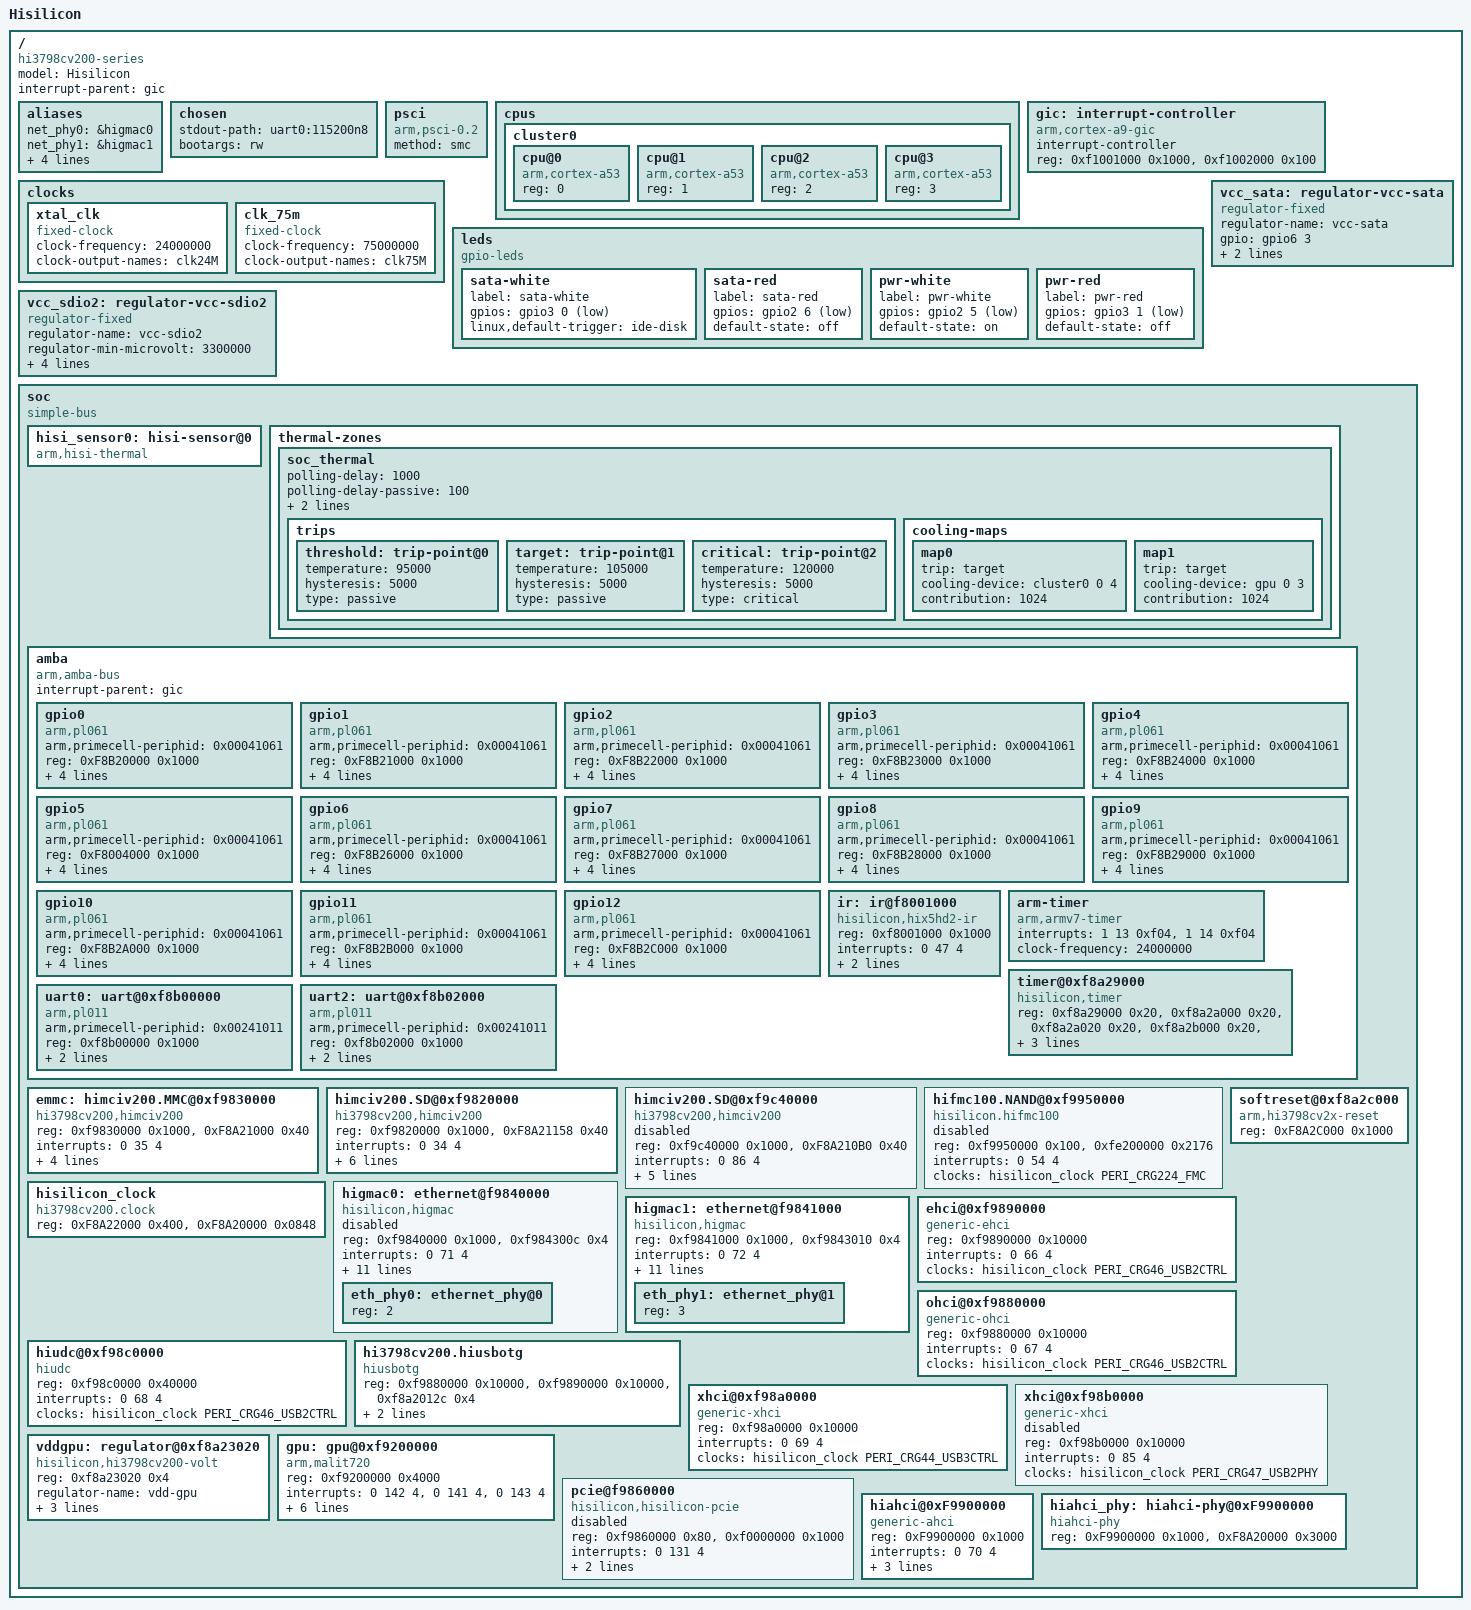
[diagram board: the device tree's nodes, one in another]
/dts-v1/;

#include <dt-bindings/clock/hi3798cv200-clock.h>
#include <dt-bindings/gpio/gpio.h>

/ {
	model = "Hisilicon";
	compatible = "hi3798cv200-series";
	#address-cells = <1>;
	#size-cells = <1>;
	interrupt-parent = <&gic>;

	aliases {
		net_phy0 = &higmac0;
		net_phy1 = &higmac1;
		net_phy_addr0 = &eth_phy0;
		net_phy_addr1 = &eth_phy1;
		emmc = &emmc;
		uart0 = &uart0;
	};

	chosen {
		stdout-path = "uart0:115200n8";
		bootargs = "rw";
	};

	psci {
		compatible = "arm,psci-0.2";
		method = "smc";
	};

	cpus {
		cluster0: cluster0 {
			#address-cells = <1>;
			#size-cells = <0>;

			/* cooling options */
			#cooling-cells = <2>; /* min followed by max */
			
			cpu@0 {
				compatible = "arm,cortex-a53";
				device_type = "cpu";
				reg = <0>;
			};
			cpu@1 {
				compatible = "arm,cortex-a53";
				device_type = "cpu";
				reg = <1>;
			};
			cpu@2 {
				compatible = "arm,cortex-a53";
				device_type = "cpu";
				reg = <2>;
			};
			cpu@3 {
				compatible = "arm,cortex-a53";
				device_type = "cpu";
				reg = <3>;
			};

		}; /* cluster0 */
	}; /* cpus */

	gic: interrupt-controller {
		compatible = "arm,cortex-a9-gic";
		#interrupt-cells = <3>;
		#address-cells = <0>;
		interrupt-controller;
		reg = <0xf1001000 0x1000>,
		      <0xf1002000 0x100>;
	};

	clocks {
		xtal_clk: xtal_clk {
			compatible = "fixed-clock";
			#clock-cells = <0>;
			clock-frequency = <24000000>;
			clock-output-names = "clk24M";
		};

		clk_75m: clk_75m{
			compatible = "fixed-clock";
			#clock-cells = <0>;
			clock-frequency = <75000000>;
			clock-output-names = "clk75M";
		};
	};

	leds {
		compatible = "gpio-leds";

		sata-white {
			label = "sata-white";
			gpios = <&gpio3 0 GPIO_ACTIVE_LOW>;
			linux,default-trigger = "ide-disk";
		};

		sata-red {
			label = "sata-red";
			gpios = <&gpio2 6 GPIO_ACTIVE_LOW>;
			default-state = "off";
		};

		pwr-white {
			label = "pwr-white";
			gpios = <&gpio2 5 GPIO_ACTIVE_LOW>;
			default-state = "on";
		};

		pwr-red {
			label = "pwr-red";
			gpios = <&gpio3 1 GPIO_ACTIVE_LOW>;
			default-state = "off";
		};
	};

	vcc_sata: regulator-vcc-sata {
		compatible = "regulator-fixed";
		regulator-name = "vcc-sata";
		gpio = <&gpio6 3 GPIO_ACTIVE_HIGH>;
		regulator-boot-on;
		enable-active-high;
	};

	vcc_sdio2: regulator-vcc-sdio2 {
		compatible = "regulator-fixed";
		regulator-name = "vcc-sdio2";
		regulator-min-microvolt = <3300000>;
		regulator-max-microvolt = <3300000>;
		gpio = <&gpio8 1 GPIO_ACTIVE_HIGH>;
		enable-active-high;
		startup-delay-us = <100000>;
	};

	soc {
		#address-cells = <1>;
		#size-cells = <1>;
		compatible = "simple-bus";
		device_type = "soc";
		ranges = <0x0 0x0 0xffffffff>;

		hisi_sensor0: hisi-sensor@0 {
			compatible = "arm,hisi-thermal";
			#thermal-sensor-cells = <1>;
		};

		thermal-zones {
			soc_thermal {
				polling-delay = <1000>;
				polling-delay-passive = <100>;
				sustainable-power = <2500>;

				thermal-sensors = <&hisi_sensor0 0>;

				trips {
					threshold: trip-point@0 {
						temperature = <95000>;
						hysteresis = <5000>;
						type = "passive";
					};
					target: trip-point@1 {
						temperature = <105000>;
						hysteresis = <5000>;
						type = "passive";
					};
					critical: trip-point@2 {
						temperature = <120000>;
						hysteresis = <5000>;
						type = "critical";
					};
				};

				cooling-maps {
					map0 {
					     trip = <&target>;
					     cooling-device = <&cluster0 0 4>;
					     contribution = <1024>;
					};
					map1 {
					    trip = <&target>;
					    cooling-device = <&gpu 0 3>;
					    contribution = <1024>;
					};
				};
			};
		};

		amba {
			compatible = "arm,amba-bus";
			#address-cells = <1>;
			#size-cells = <1>;
			interrupt-parent = <&gic>;
			ranges;

			gpio0: gpio0 {
				compatible = "arm,pl061", "arm,primecell";
				arm,primecell-periphid = <0x00041061>;
				reg = <0xF8B20000 0x1000>;
				interrupts = <0 108 0x4>;
				gpio-controller;
				#gpio-cells = <2>;
				interrupt-controller;
				#interrupt-cells = <2>;
				clocks = <&xtal_clk>;
				clock-names = "apb_pclk";
			};

			gpio1: gpio1 {
				compatible = "arm,pl061", "arm,primecell";
				arm,primecell-periphid = <0x00041061>;
				reg = <0xF8B21000 0x1000>;
				interrupts = <0 109 4>;
				gpio-controller;
				#gpio-cells = <2>;
				interrupt-controller;
				#interrupt-cells = <2>;
				clocks = <&xtal_clk>;
				clock-names = "apb_pclk";
			};

			gpio2: gpio2 {
				compatible = "arm,pl061", "arm,primecell";
				arm,primecell-periphid = <0x00041061>;
				reg = <0xF8B22000 0x1000>;
				interrupts = <0 110 4>;
				gpio-controller;
				#gpio-cells = <2>;
				interrupt-controller;
				#interrupt-cells = <2>;
				clocks = <&xtal_clk>;
				clock-names = "apb_pclk";
			};

			gpio3: gpio3 {
				compatible = "arm,pl061", "arm,primecell";
				arm,primecell-periphid = <0x00041061>;
				reg = <0xF8B23000 0x1000>;
				interrupts = <0 111 4>;
				gpio-controller;
				#gpio-cells = <2>;
				interrupt-controller;
				#interrupt-cells = <2>;
				clocks = <&xtal_clk>;
				clock-names = "apb_pclk";
			};

			gpio4: gpio4 {
				compatible = "arm,pl061", "arm,primecell";
				arm,primecell-periphid = <0x00041061>;
				reg = <0xF8B24000 0x1000>;
				interrupts = <0 112 4>;
				gpio-controller;
				#gpio-cells = <2>;
				interrupt-controller;
				#interrupt-cells = <2>;
				clocks = <&xtal_clk>;
				clock-names = "apb_pclk";
			};

			gpio5: gpio5 {
				compatible = "arm,pl061", "arm,primecell";
				arm,primecell-periphid = <0x00041061>;
				reg = <0xF8004000 0x1000>;
				interrupts = <0 113 0>;
				gpio-controller;
				#gpio-cells = <2>;
				interrupt-controller;
				#interrupt-cells = <2>;
				clocks = <&xtal_clk>;
				clock-names = "apb_pclk";
			};

			gpio6: gpio6 {
				compatible = "arm,pl061", "arm,primecell";
				arm,primecell-periphid = <0x00041061>;
				reg = <0xF8B26000 0x1000>;
				interrupts = <0 114 4>;
				gpio-controller;
				#gpio-cells = <2>;
				interrupt-controller;
				#interrupt-cells = <2>;
				clocks = <&xtal_clk>;
				clock-names = "apb_pclk";
			};

			gpio7: gpio7 {
				compatible = "arm,pl061", "arm,primecell";
				arm,primecell-periphid = <0x00041061>;
				reg = <0xF8B27000 0x1000>;
				interrupts = <0 115 4>;
				gpio-controller;
				#gpio-cells = <2>;
				interrupt-controller;
				#interrupt-cells = <2>;
				clocks = <&xtal_clk>;
				clock-names = "apb_pclk";
			};

			gpio8: gpio8 {
				compatible = "arm,pl061", "arm,primecell";
				arm,primecell-periphid = <0x00041061>;
				reg = <0xF8B28000 0x1000>;
				interrupts = <0 116 4>;
				gpio-controller;
				#gpio-cells = <2>;
				interrupt-controller;
				#interrupt-cells = <2>;
				clocks = <&xtal_clk>;
				clock-names = "apb_pclk";
			};

			gpio9: gpio9 {
				compatible = "arm,pl061", "arm,primecell";
				arm,primecell-periphid = <0x00041061>;
				reg = <0xF8B29000 0x1000>;
				interrupts = <0 117 4>;
				gpio-controller;
				#gpio-cells = <2>;
				interrupt-controller;
				#interrupt-cells = <2>;
				clocks = <&xtal_clk>;
				clock-names = "apb_pclk";
			};

			gpio10: gpio10 {
				compatible = "arm,pl061", "arm,primecell";
				arm,primecell-periphid = <0x00041061>;
				reg = <0xF8B2A000 0x1000>;
				interrupts = <0 118 4>;
				gpio-controller;
				#gpio-cells = <2>;
				interrupt-controller;
				#interrupt-cells = <2>;
				clocks = <&xtal_clk>;
				clock-names = "apb_pclk";
			};

			gpio11: gpio11 {
				compatible = "arm,pl061", "arm,primecell";
				arm,primecell-periphid = <0x00041061>;
				reg = <0xF8B2B000 0x1000>;
				interrupts = <0 119 4>;
				gpio-controller;
				#gpio-cells = <2>;
				interrupt-controller;
				#interrupt-cells = <2>;
				clocks = <&xtal_clk>;
				clock-names = "apb_pclk";
			};

			gpio12: gpio12 {
				compatible = "arm,pl061", "arm,primecell";
				arm,primecell-periphid = <0x00041061>;
				reg = <0xF8B2C000 0x1000>;
				interrupts = <0 120 4>;
				gpio-controller;
				#gpio-cells = <2>;
				interrupt-controller;
				#interrupt-cells = <2>;
				clocks = <&xtal_clk>;
				clock-names = "apb_pclk";
			};

			ir: ir@f8001000 {
				compatible = "hisilicon,hix5hd2-ir";
				reg = <0xf8001000 0x1000>;
				interrupts = <0 47 4>;
				clocks = <&hisilicon_clock HIIR_CLK>;
				linux,rc-map-name = "rc-atto";
			};

			arm-timer {
				compatible = "arm,armv7-timer";
				interrupts = <1 13 0xf04>,
				             <1 14 0xf04>;
				clock-frequency = <24000000>;
			};

			timer@0xf8a29000 {
				compatible = "hisilicon,timer";
				reg = <0xf8a29000 0x20>, /* clocksource */
				      <0xf8a2a000 0x20>, /* local timer for each cpu */
				      <0xf8a2a020 0x20>,
				      <0xf8a2b000 0x20>,
				      <0xf8a2b020 0x20>;
				interrupts = <0 26 4>, /* irq of local timer */
					     <0 59 4>,
					     <0 27 4>,
					     <0 60 4>;
				clocks = <&xtal_clk>;
				clock-names = "apb_pclk";
			};

			uart0: uart@0xf8b00000 {
				compatible = "arm,pl011", "arm,primecell";
				arm,primecell-periphid = <0x00241011>;
				reg = <0xf8b00000 0x1000>;
				interrupts = <0 49 4>;
				clocks = <&clk_75m>;
				clock-names = "apb_pclk";
			};

			uart2: uart@0xf8b02000 {
				compatible = "arm,pl011", "arm,primecell";
				arm,primecell-periphid = <0x00241011>;
				reg = <0xf8b02000 0x1000>;
				interrupts = <0 51 4>;
				clocks = <&clk_75m>;
				clock-names = "apb_pclk";
			};

		};

		emmc: himciv200.MMC@0xf9830000 {
			compatible = "hi3798cv200,himciv200";
			reg = <0xf9830000 0x1000>,<0xF8A21000 0x40>;
			interrupts = <0 35 4>;

			clocks = <&hisilicon_clock PERI_CRG40_SDIO1>;
			clock-names = "clk";

			caps = <0x80000847>;
			caps2 = <0x0>;
			max-frequency = <100000000>;
			status = "okay";
		};

		himciv200.SD@0xf9820000 {
			compatible = "hi3798cv200,himciv200";
			reg = <0xf9820000 0x1000>,<0xF8A21158 0x40>;
			interrupts = <0 34 4>;

			clocks = <&hisilicon_clock PERI_CRG39_SDIO0>;
			clock-names = "clk";

			ldo-addr  = <0xf8a2011c>;
			ldo-shift = <0>;

			caps = <0x8000000f>;
			caps2 = <0x4000>;
			max-frequency = <50000000>;
			status = "okay";
		};

		himciv200.SD@0xf9c40000 {
			compatible = "hi3798cv200,himciv200";
			reg = <0xf9c40000 0x1000>,<0xF8A210B0 0x40>;
			interrupts = <0 86 4>;

			clocks = <&hisilicon_clock PERI_CRG163_SDIO2>;
			clock-names = "clk";

			caps = <0x8000000f>;
			caps2 = <0x4000>;
			max-frequency = <50000000>;
			vmmc-supply = <&vcc_sdio2>;
			status = "disabled";
		};

		hifmc100.NAND@0xf9950000 {
			compatible = "hisilicon.hifmc100";
			reg = <0xf9950000 0x100>, <0xfe200000 0x2176>;
			interrupts = <0 54 4>;

			clocks = <&hisilicon_clock PERI_CRG224_FMC>;
			clock-names = "clk";
			status = "disabled";
		};

		hisilicon_clock: hisilicon_clock {
			compatible = "hi3798cv200.clock","hisilicon,clock-reset";
			reg = <0xF8A22000 0x400>, <0xF8A20000 0x0848>;
			#clock-cells = <1>;
			#reset-cells = <2>;
		};

		higmac0: ethernet@f9840000 {
			compatible = "hisilicon,higmac";
			reg = <0xf9840000 0x1000>,<0xf984300c 0x4>;
			interrupts = <0 71 4>;

			clocks = <&hisilicon_clock HIGMAC_MAC0_CLK>,
					<&hisilicon_clock HIGMAC_MAC_IF0_CLK>;
			clock-names = "higmac_clk",
					"macif_clk";

			resets = <&hisilicon_clock PERI_CRG51_GSF HIGMAC_PORT0_RST_BIT>,
					<&hisilicon_clock PERI_CRG51_GSF HIGMAC_MACIF0_RST_BIT>,
					<&hisilicon_clock PERI_CRG51_GSF HIGMAC_PHY0_RST_BIT>;
			reset-names = "port_reset",
					"macif_reset",
					"phy_reset";

			#address-cells = <1>;
			#size-cells = <0>;

			mac-address = [00 00 00 00 00 00];

			phy-handle = <&eth_phy0>;
			phy-mode = "mii";
			phy-gpio-base = <0>;
			phy-gpio-bit = <0>;

			status = "disabled";

			eth_phy0: ethernet_phy@0 {
				reg = <2>;
			};
		};

		higmac1: ethernet@f9841000 {
			compatible = "hisilicon,higmac";
			reg = <0xf9841000 0x1000>,<0xf9843010 0x4>;
			interrupts = <0 72 4>;

			clocks = <&hisilicon_clock HIGMAC_MAC1_CLK>,
					<&hisilicon_clock HIGMAC_MAC_IF1_CLK>;
			clock-names = "higmac_clk",
					"macif_clk";

			resets = <&hisilicon_clock PERI_CRG51_GSF HIGMAC_PORT1_RST_BIT>,
					<&hisilicon_clock PERI_CRG51_GSF HIGMAC_MACIF1_RST_BIT>,
					<&hisilicon_clock PERI_CRG51_GSF HIGMAC_PHY1_RST_BIT>;
			reset-names = "port_reset",
					"macif_reset",
					"phy_reset";

			#address-cells = <1>;
			#size-cells = <0>;

			mac-address = [00 00 00 00 00 00];

			phy-handle = <&eth_phy1>;
			phy-mode = "rgmii-id";
			phy-gpio-base = <0>;
			phy-gpio-bit = <0>;

			status = "okay";

			eth_phy1: ethernet_phy@1{
				reg = <3>;
			};
		};

		softreset@0xf8a2c000 {
			compatible = "arm,hi3798cv2x-reset";
			reg = <0xF8A2C000 0x1000>;
		};

		ehci@0xf9890000 {
			compatible = "generic-ehci";
			reg = <0xf9890000 0x10000>;
			interrupts = <0 66 4>;

			clocks = <&hisilicon_clock PERI_CRG46_USB2CTRL>;
			clock-names = "clk";
		};

		ohci@0xf9880000 {
			compatible = "generic-ohci";
			reg = <0xf9880000 0x10000>;
			interrupts = <0 67 4>;

			clocks = <&hisilicon_clock PERI_CRG46_USB2CTRL>;
			clock-names = "clk";
		};

		hiudc@0xf98c0000 {
			compatible = "hiudc";
			reg = <0xf98c0000 0x40000>;
			interrupts = <0 68 4>;

			clocks = <&hisilicon_clock PERI_CRG46_USB2CTRL>;
			clock-names = "clk";
		};

		hi3798cv200.hiusbotg {
			compatible = "hiusbotg";
			reg = <0xf9880000 0x10000>,<0xf9890000 0x10000>,<0xf8a2012c 0x4>;
			host_time = <1500 4>;
			device_time = <1000 4>;
		};

		xhci@0xf98a0000 {
			compatible = "generic-xhci";
			reg = <0xf98a0000 0x10000>;
			interrupts = <0 69 4>;

			clocks = <&hisilicon_clock PERI_CRG44_USB3CTRL>;
			clock-names = "clk";
			status = "okay";
		};

		xhci@0xf98b0000 {
			compatible = "generic-xhci";
			reg = <0xf98b0000 0x10000>;
			interrupts = <0 85 4>;

			clocks = <&hisilicon_clock PERI_CRG47_USB2PHY>;
			clock-names = "clk";
			status = "disabled";
		};

		vddgpu: regulator@0xf8a23020 {
			compatible = "hisilicon,hi3798cv200-volt";
			reg = <0xf8a23020 0x4>;
			reg-names = "base-address";
			regulator-name = "vdd-gpu";
			regulator-min-microvolt = <650000>;
			regulator-max-microvolt = <1150000>;
			regulator-always-on;
		};

		gpu:gpu@0xf9200000 {
			compatible = "arm,malit720", "arm,mali", "arm,mali-midgard";
			reg = <0xf9200000 0x4000>;
			interrupts = <0 142 4>, <0 141 4>, <0 143 4>;
			interrupt-names = "JOB", "MMU", "GPU";

			#cooling-cells = <2>; /* min followed by max */

			clocks = <&hisilicon_clock PERI_CRG73_GPU_LP>;
			clock-names = "clk_mali";
			mali-supply = <&vddgpu>;
			operating-points = <
			200000 880000
			300000 880000
			400000 880000
			600000 1120000>;

			cooling-min-state = <0>;
			cooling-max-state = <3>;

		};

		pcie@f9860000 {
			compatible = "hisilicon,hisilicon-pcie","snps,dw-pcie";
			reg = <0xf9860000 0x80>,<0xf0000000 0x1000>;
			interrupts = <0 131 4>;

			clocks = <&hisilicon_clock PERI_CRG99_PCIECTRL>;
			clock-names = "clk";

			#address-cells = <3>;
			#size-cells = <2>;
			device_type = "pci";
			ranges=<0x00000800 0 0xf2100000 0xf2100000 0 0x00020000
				0x81000000 0 0 0xf4000000 0 0x00010000
				0x82000000 0 0xf3000000 0xf3000000 0 0x01000000>;
			num-lanes = <1>;
			status = "disabled";
		};

		hiahci@0xF9900000 {
			compatible = "generic-ahci";
			reg = <0xF9900000 0x1000>;
			interrupts = <0 70 4>;

			phys = <&hiahci_phy>;
			phy-names = "sata-phy";

			clocks = <&hisilicon_clock PERI_CRG42_SATA3CTRL>;
			clock-names = "clk";
			target-supply = <&vcc_sata>;
			status = "okay";
		};

		hiahci_phy: hiahci-phy@0xF9900000 {
			compatible = "hiahci-phy";
			reg = <0xF9900000 0x1000>,<0xF8A20000 0x3000>;
			#phy-cells = <0>;
		};
	};
};
